# NUC400_v1 register map
File version: 1.0
Registers are 32-bit, read-write, reset 0x0 unless marked. A register's access mark holds for its fields unless they carry their own. Offsets are from the block's base; [hi:lo] are bit positions; lines under a group give offsets from that group; 'fields as' and 'values as' point back to an identical list.

## TIMER23 — TIMER Register Map
Base 0x40051000
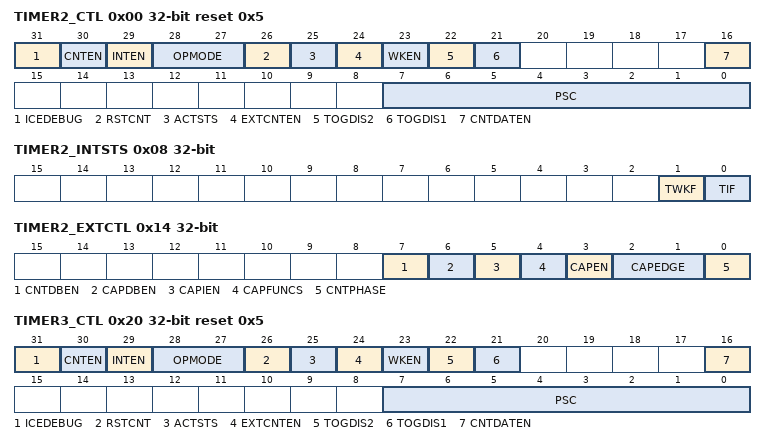
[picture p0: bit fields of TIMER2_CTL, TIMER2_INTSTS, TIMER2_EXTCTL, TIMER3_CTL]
0x00 TIMER2_CTL reset 0x5 — Timer2 Control and Status Register
  [31] ICEDEBUG — ICE Debug Mode Acknowledge Disable Bit (Write Protect). TIMER counter will keep going no matter CPU is held by ICE or not.
    0=ICE debug mode acknowledgement effects TIMER counting; 1=ICE debug mode acknowledgement Disabled
  [30] CNTEN — Timer Enable Bit
    0=Stops/Suspends counting; 1=Starts counting
  [29] INTEN — Interrupt Enable Bit. If this bit is enabled, when the timer interrupt flag TIF is set to 1, the timer interrupt signal is generated and inform to CPU.
    0=Timer Interrupt Disabled; 1=Timer Interrupt Enabled
  [28:27] OPMODE — Timer Operation Mode
    0=The Timer controller is operated in One-shot mode; 1=The Timer controller is operated in Periodic mode; 2=The Timer controller is operated in Toggle-output mode; 3=The Timer controller is operated in Continuous Counting mode
  [26] RSTCNT — Timer Reset Bit. Setting this bit will reset the 24-bit up counter value (TIMERx_CNT) and also force CNTEN (TIMERx_CTL[30]) to 0 if ACTSTS (TIMERx_CTL[25]) is 1.
    0=No effect; 1=Reset 8-bit PSC counter, 24-bit up counter value and CNTEN bit
  [25] ACTSTS ro — Timer Active Status Bit (Read Only). This bit indicates the 24-bit up counter status.
    0=24-bit up counter is not active; 1=24-bit up counter is active
  [24] EXTCNTEN — Counter Mode Enable Bit. This bit is for external counting pin function enabled. When timer is used as an event counter, this bit should be set to 1 and select PCLK as timer clock source.
    0=External counter mode Disabled; 1=External counter mode Enabled
  [23] WKEN — Wake-Up Enable. If this bit is set to 1, while timer interrupt flag TIF (TIMERx_INTSTS[0]) is 1 and INTEN (TIMERx_CTL[29]) is enabled, the timer interrupt signal will generate a wake-up trigger event to CPU.
    0=Wake-up trigger event Disabled if timer interrupt signal generated; 1=Wake-up trigger event Enabled if timer interrupt signal generated
  [22] TOGDIS2 — Toggle Output 2 Disable. Setting this bit will disable the Toggle output pins group 2. Note1: If both TOUT1 (group 1 pins) and TOUT2 (group 2 pins) function are enabled, toggle output signal is generated only from TOUT1 pins. Note2: The group2 pins are PD1, PE8, PE1, and PD11.
    0=Toggle output pins group 2 Enabled; 1=Toggle output pins group 2 Disabled
  [21] TOGDIS1 — Toggle Output 1 Disable. Setting this bit will disable the Toggle output pins group 1. Note: The group1 pins are PB4, PB1, PC6, and PC1.
    0=Toggle output pins group 1 Enabled; 1=Toggle output pins group 1 Disabled
  [16] CNTDATEN — Data Load Enable. When this bit is set, timer counter value (TIMERx_CNT) will be updated continuously to monitor internal 24-bit up counter value as the counter is counting.
    0=Timer Data Register update Disabled; 1=Timer Data Register update Enabled while timer counter is active
  [7:0] PSC — PSC Counter
0x04 TIMER2_CMP — Timer2 Compare Register
  [23:0] CMPDAT — Timer Compared Value. CMPDAT is a 24-bit compared value register. When the internal 24-bit up counter value is equal to CMPDAT value, the TIF (TIMERx_INTSTS[0] timer interrupt flag) will set to 1. Note1: Never write 0x0 or 0x1 in CMPDAT field, or the timer will run into unknown state. Note2: When timer is operating at continuous counting mode, the 24-bit up counter will keep counting continuously even if software writes a new value into CMPDAT field. But if timer is operating at other modes, the 24-bit up counter will restart counting and using newest CMPDAT value to be the timer compared value if software writes a new value into CMPDAT field.
0x08 TIMER2_INTSTS — Timer2 Interrupt Status Register
  [1] TWKF — Timer Wake-Up Flag. This bit indicates the interrupt wake-up flag status of timer. Note: This bit is cleared by writing 1 to it.
    0=Timer does not cause CPU wake-up; 1=CPU wake-up from Idle or power-down mode if timer time-out interrupt signal generated
  [0] TIF — Timer Interrupt Flag. This bit indicates the interrupt flag status of Timer while TIMERx_CNT value reaches to CMPDAT value. Note: This bit is cleared by writing 1 to it.
    0=No effect; 1=TIMERx_CNT value matches the CMPDAT value
0x0C TIMER2_CNT ro — Timer2 Data Register
  [23:0] CNT — Timer Data Register. User can read CNT for getting current 24- bit event counter value if TIMERx_CTL[24] is 1
0x10 TIMER2_CAP ro — Timer2 Capture Data Register
  [23:0] CAPDAT — Timer Capture Data Register. When CAPEN (TIMERx_EXTCTL[3]) bit is set, CAPFUNCS (TIMERx_EXTCTL[4]) bit is 0, and a transition on TMx_EXT pin matched the CAPEDGE (TIMERx_EXTCTL[2:1]) setting, CAPIF (TIMERx_EINTSTS[0]) will set to 1 and the current timer counter value (TIMERx_CNT value) will be auto-loaded into this CAPDAT field.
0x14 TIMER2_EXTCTL — Timer2 External Control Register
  [7] CNTDBEN — Timer Counter Pin De-Bounce Enable. If this bit is enabled, the edge detection of TMx pin is detected with de-bounce circuit.
    0=TMx (x= 0~3) pin de-bounce Disabled; 1=TMx (x= 0~3) pin de-bounce Enabled
  [6] CAPDBEN — Timer External Capture Pin De-Bounce Enable. If this bit is enabled, the edge detection of TMx_EXT pin is detected with de-bounce circuit.
    0=TMx_EXT (x= 0~3) pin de-bounce Disabled; 1=TMx_EXT (x= 0~3) pin de-bounce Enabled
  [5] CAPIEN — Timer External Interrupt Enable
    0=TMx_EXT (x= 0~3) pin detection Interrupt Disabled; 1=TMx_EXT (x= 0~3) pin detection Interrupt Enabled
  [4] CAPFUNCS — Timer External Reset Counter / Capture Mode Select
    0=Transition on TMx_EXT (x= 0~3) pin is using to save the 24-bit timer counter value; 1=Transition on TMx_EXT (x= 0~3) pin is using to reset the 24-bit timer counter value
  [3] CAPEN — Timer External Pin Enable. This bit enables the CAPFUNCS (TIMERx_EXTCTL[4]) function on the TMx_EXT pin.
    0=CAPFUNCS function of TMx_EXT (x= 0~3) pin will be ignored; 1=CAPFUNCS function of TMx_EXT (x= 0~3) pin is active
  [2:1] CAPEDGE — Timer External Pin Edge Detect
    0=A 1 to 0 transition on TMx_EXT (x= 0~3) pin will be detected; 1=A 0 to 1 transition on TMx_EXT (x= 0~3) pin will be detected; 2=Either 1 to 0 or 0 to 1 transition on TMx_EXT (x= 0~3) pin will be detected
  [0] CNTPHASE — Timer External Count Phase. This bit indicates the detection phase of external counting pin.
    0=A falling edge of external counting pin will be counted; 1=A rising edge of external counting pin will be counted
0x18 TIMER2_EINTSTS — Timer2 External Interrupt Status Register
  [0] CAPIF — Timer External Interrupt Flag. This bit indicates the timer external interrupt flag status. Note: This bit is cleared by writing 1 to it.
    0=TMx_EXT (x= 0~3) pin interrupt did not occur; 1=TMx_EXT (x= 0~3) pin interrupt occurred
0x20 TIMER3_CTL reset 0x5 — Timer3 Control and Status Register
  fields as TIMER2_CTL
0x24 TIMER3_CMP — Timer3 Compare Register
  fields as TIMER2_CMP
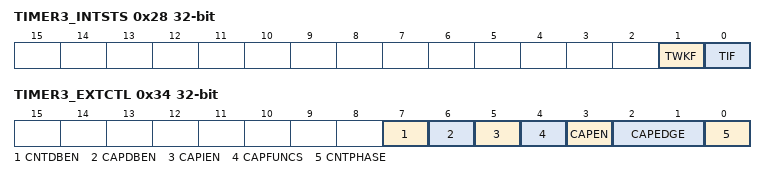
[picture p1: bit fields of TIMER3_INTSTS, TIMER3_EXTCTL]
0x28 TIMER3_INTSTS — Timer3 Interrupt Status Register
  fields as TIMER2_INTSTS
0x2C TIMER3_CNT ro — Timer3 Data Register
  fields as TIMER2_CNT
0x30 TIMER3_CAP ro — Timer3 Capture Data Register
  fields as TIMER2_CAP
0x34 TIMER3_EXTCTL — Timer3 External Control Register
  fields as TIMER2_EXTCTL
0x38 TIMER3_EINTSTS — Timer3 External Interrupt Status Register
  fields as TIMER2_EINTSTS
